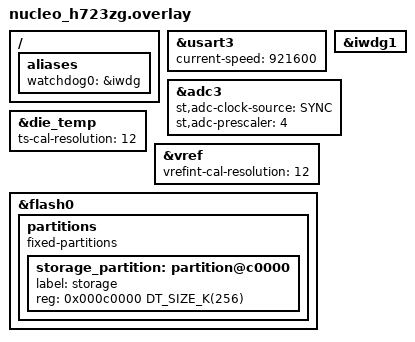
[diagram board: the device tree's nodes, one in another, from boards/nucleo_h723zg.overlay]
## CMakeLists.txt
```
cmake_minimum_required(VERSION 3.20.0)
find_package(Zephyr REQUIRED HINTS $ENV{ZEPHYR_BASE})
project(motor)

target_sources(app PRIVATE src/main.c src/control.c src/tune.c src/health.c src/settings.c)
```

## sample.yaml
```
sample:
  name: Motor controller node
common:
  platform_allow:
    - nucleo_h723zg
    - nucleo_h753zi
  integration_platforms:
    - nucleo_h753zi
tests:
  zelos.nodes.motor: {}
```

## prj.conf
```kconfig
# A motor controller whose debug interface is its serial console: Zephyr's log
# and its shell share the board's console UART.
CONFIG_LOG=y
CONFIG_SHELL=y

# Deferred logging, so the control loop copies a message into a buffer and
# never waits on the UART. 16 KiB holds about a second of output at full rate.
CONFIG_LOG_MODE_DEFERRED=y
CONFIG_LOG_BUFFER_SIZE=16384
# Flush every message, so command replies never land among stale lines.
CONFIG_LOG_PROCESS_TRIGGER_THRESHOLD=1
# printk goes through the log too, unprefixed: the Teleplot points.
CONFIG_LOG_PRINTK=y

# The control law runs in single-precision float on the Cortex-M7's FPU, and
# the log prints floats.
CONFIG_FPU=y
CONFIG_CBPRINTF_FP_SUPPORT=y

# LEDs, the user button, and the die temperature and VREF sensors.
CONFIG_GPIO=y
CONFIG_SENSOR=y
CONFIG_ADC=y

# CPU load, from the scheduler's own cycle accounting.
CONFIG_THREAD_RUNTIME_STATS=y
CONFIG_SCHED_THREAD_USAGE_ALL=y

# Why the board last reset: power-on, pin, software, watchdog or a crash.
CONFIG_HWINFO=y

# The hardware watchdog: a stalled control loop resets the board.
CONFIG_WATCHDOG=y

# Tuning saved to flash, so it survives a reset. ZMS, not NVS: NVS addresses
# at most 64 KiB sectors, and the STM32H7 erases 128 KiB at a time.
CONFIG_FLASH=y
CONFIG_FLASH_MAP=y
CONFIG_ZMS=y
CONFIG_SETTINGS=y
CONFIG_SETTINGS_ZMS=y

# A crash prints its dump, records where it happened, and the board restarts,
# as a field unit would; main.c's fatal error handler does the restart.
CONFIG_REBOOT=y
CONFIG_THREAD_NAME=y

# The control loop, the health thread and the shell all use the FPU.
CONFIG_FPU_SHARING=y

CONFIG_MAIN_STACK_SIZE=4096
CONFIG_SHELL_STACK_SIZE=4096
```

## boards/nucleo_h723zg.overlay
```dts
/*
 * NUCLEO-H723ZG: the board the serial-board bench runs on. The board file
 * enables none of these, so the node does.
 */

/ {
	aliases {
		watchdog0 = &iwdg;
	};
};

/* The console at 921600 baud: the ST-LINK-V3's virtual COM port carries it. */
&usart3 {
	current-speed = <921600>;
};

&iwdg1 {
	status = "okay";
};

/* The die temperature and VREFINT sensors read internal channels of ADC3. */
&adc3 {
	st,adc-clock-source = "SYNC";
	st,adc-prescaler = <4>;
	status = "okay";
};

/*
 * The H72x keeps its factory calibration of these channels at ADC3's 12-bit
 * resolution; the H7 family file says 16, which reads VDDA 16 times too low.
 */
&die_temp {
	ts-cal-resolution = <12>;
	status = "okay";
};

&vref {
	vrefint-cal-resolution = <12>;
	status = "okay";
};

/* The last two 128 KiB sectors hold the saved tuning. */
&flash0 {
	partitions {
		compatible = "fixed-partitions";
		#address-cells = <1>;
		#size-cells = <1>;

		storage_partition: partition@c0000 {
			label = "storage";
			reg = <0x000c0000 DT_SIZE_K(256)>;
		};
	};
};
```

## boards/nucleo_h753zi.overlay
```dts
/* NUCLEO-H753ZI, the board CI builds every node for: the same console speed and sensors. */

&usart3 {
	current-speed = <921600>;
};

&vref {
	status = "okay";
};
```

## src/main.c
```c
/*
 * Motor controller.
 *
 * A brushed DC motor speed controller whose debug interface is its serial
 * console, the way most boards on a bench are brought up. The log and the
 * shell share the console UART:
 *
 *   motor target <rpm>    the speed target, -6000 to 6000
 *   motor load <Nm>       an external load torque, 0 to 0.15
 *   motor stop | status
 *   pid show | save | defaults
 *   pid kp|ki|kd <value>  tune the speed loop live
 *   fault crash | hang | dump
 *
 * At boot it logs its version, why the board reset, and, if the last run
 * crashed, where. A crash record lives in RAM that survives the reset.
 */

#include <stdlib.h>
#include <string.h>

#include <zephyr/drivers/hwinfo.h>
#include <zephyr/fatal.h>
#include <zephyr/kernel.h>
#include <zephyr/linker/section_tags.h>
#include <zephyr/logging/log.h>
#include <zephyr/logging/log_ctrl.h>
#include <zephyr/shell/shell.h>
#include <zephyr/sys/reboot.h>

#include "motor.h"

LOG_MODULE_REGISTER(app, LOG_LEVEL_INF);

#define CRASH_MAGIC 0xC0FFEE42u

/* Not cleared at boot: written by the fatal error handler, read after the reset. */
static __noinit struct {
	uint32_t magic;
	uint32_t reason;
	uint32_t pc;
	char thread[16];
} crash;

void k_sys_fatal_error_handler(unsigned int reason, const struct arch_esf *esf)
{
	const char *name = k_thread_name_get(k_current_get());

	crash.magic = CRASH_MAGIC;
	crash.reason = reason;
	crash.pc = esf != NULL ? esf->basic.pc : 0;
	strncpy(crash.thread, name != NULL ? name : "?", sizeof(crash.thread) - 1);
	crash.thread[sizeof(crash.thread) - 1] = '\0';

	LOG_ERR("rebooting after fatal error %u", reason);
	LOG_PANIC();
	sys_reboot(SYS_REBOOT_COLD);
	CODE_UNREACHABLE;
}

static const char *reset_cause(uint32_t cause)
{
	/* The most telling cause first: a watchdog reset also sets the pin flag. */
	if (cause & RESET_WATCHDOG) {
		return "watchdog";
	}
	if (cause & RESET_SOFTWARE) {
		return "software";
	}
	if (cause & RESET_BROWNOUT) {
		return "brownout";
	}
	if (cause & RESET_POR) {
		return "power-on";
	}
	if (cause & RESET_PIN) {
		return "reset-pin";
	}
	return "unknown";
}

static void report_boot(void)
{
	uint32_t cause = 0;

	hwinfo_get_reset_cause(&cause);
	hwinfo_clear_reset_cause();

	LOG_INF("motor-ctl v%s board=%s reset=%s", FW_VERSION, CONFIG_BOARD, reset_cause(cause));

	if (crash.magic == CRASH_MAGIC) {
		LOG_ERR("previous run crashed reason=%u pc=0x%08x thread=%s", crash.reason,
			crash.pc, crash.thread);
	} else if (cause & RESET_WATCHDOG) {
		LOG_ERR("previous run stopped feeding the watchdog");
	}
	crash.magic = 0;
}

/* "1500", "-2.5" and "0.05" are numbers; "", "12x" and "1e999" are not. */
static int parse(const struct shell *sh, const char *s, float lo, float hi, float *out)
{
	char *end;
	const float v = strtof(s, &end);

	if (end == s || *end != '\0' || v < lo || v > hi) {
		shell_error(sh, "expected a number from %g to %g", (double)lo, (double)hi);
		return -EINVAL;
	}
	*out = v;
	return 0;
}

static int cmd_target(const struct shell *sh, size_t argc, char **argv)
{
	float rpm;

	if (parse(sh, argv[1], -6000.0f, 6000.0f, &rpm) != 0) {
		return -EINVAL;
	}
	control_set_target(rpm);
	shell_print(sh, "target %.0f rpm", (double)rpm);
	return 0;
}

static int cmd_load(const struct shell *sh, size_t argc, char **argv)
{
	float nm;

	if (parse(sh, argv[1], 0.0f, 0.15f, &nm) != 0) {
		return -EINVAL;
	}
	control_set_load(nm);
	shell_print(sh, "load %.3f Nm", (double)nm);
	return 0;
}

static int cmd_stop(const struct shell *sh, size_t argc, char **argv)
{
	control_set_target(0.0f);
	shell_print(sh, "target 0 rpm");
	return 0;
}

static int cmd_status(const struct shell *sh, size_t argc, char **argv)
{
	const struct pid_gains g = control_gains();

	shell_print(sh, "target   %.0f rpm", (double)control_target());
	shell_print(sh, "load     %.3f Nm", (double)control_load());
	shell_print(sh, "limiting %s", control_limiting() ? "yes" : "no");
	shell_print(sh, "winding  %.1f C", (double)control_winding_c());
	shell_print(sh, "gains    kp=%.4f ki=%.3f kd=%.4f", (double)g.kp, (double)g.ki,
		    (double)g.kd);
	return 0;
}

static int cmd_pid_show(const struct shell *sh, size_t argc, char **argv)
{
	const struct pid_gains g = control_gains();

	shell_print(sh, "kp %.4f A/rpm", (double)g.kp);
	shell_print(sh, "ki %.3f A/(rpm s)", (double)g.ki);
	shell_print(sh, "kd %.4f A s/rpm", (double)g.kd);
	return 0;
}

static int cmd_pid_gain(const struct shell *sh, size_t argc, char **argv)
{
	struct pid_gains g = control_gains();
	float *field = strcmp(argv[0], "kp") == 0   ? &g.kp
		       : strcmp(argv[0], "ki") == 0 ? &g.ki
						    : &g.kd;
	float v;

	if (parse(sh, argv[1], 0.0f, 10.0f, &v) != 0) {
		return -EINVAL;
	}
	*field = v;
	control_set_gains(g);
	tuning_report("gains changed");
	shell_print(sh, "%s %g", argv[0], (double)v);
	return 0;
}

static int cmd_pid_save(const struct shell *sh, size_t argc, char **argv)
{
	return tuning_save();
}

static int cmd_pid_defaults(const struct shell *sh, size_t argc, char **argv)
{
	control_set_gains(PID_DEFAULTS);
	tuning_report("gains reset to defaults");
	return 0;
}

static int cmd_fault_crash(const struct shell *sh, size_t argc, char **argv)
{
	LOG_WRN("executing an undefined instruction on purpose");
	k_msleep(20);
	/* A real CPU exception, the kind a corrupted function pointer causes. */
	__asm__ volatile("udf #0");
	return 0;
}

static int cmd_fault_hang(const struct shell *sh, size_t argc, char **argv)
{
	LOG_WRN("stalling the control loop on purpose; the watchdog resets the board in 100 ms");
	k_msleep(20);
	control_stall();
	return 0;
}

static int cmd_fault_dump(const struct shell *sh, size_t argc, char **argv)
{
	const struct pid_gains g = control_gains();

	LOG_HEXDUMP_INF(&g, sizeof(g), "pid gains as stored in flash");
	return 0;
}

SHELL_STATIC_SUBCMD_SET_CREATE(motor_cmds,
	SHELL_CMD_ARG(target, NULL, "<rpm>  Speed target, -6000 to 6000", cmd_target, 2, 0),
	SHELL_CMD_ARG(load, NULL, "<Nm>  Load torque, 0 to 0.15", cmd_load, 2, 0),
	SHELL_CMD_ARG(stop, NULL, "Target 0 rpm", cmd_stop, 1, 0),
	SHELL_CMD_ARG(status, NULL, "Show the controller's state", cmd_status, 1, 0),
	SHELL_SUBCMD_SET_END);
SHELL_CMD_REGISTER(motor, &motor_cmds, "Motor speed control", NULL);

SHELL_STATIC_SUBCMD_SET_CREATE(pid_cmds,
	SHELL_CMD_ARG(show, NULL, "Show the speed loop's gains", cmd_pid_show, 1, 0),
	SHELL_CMD_ARG(kp, NULL, "<value>  Proportional gain, A/rpm", cmd_pid_gain, 2, 0),
	SHELL_CMD_ARG(ki, NULL, "<value>  Integral gain, A/(rpm s)", cmd_pid_gain, 2, 0),
	SHELL_CMD_ARG(kd, NULL, "<value>  Derivative gain, A s/rpm", cmd_pid_gain, 2, 0),
	SHELL_CMD_ARG(save, NULL, "Save the gains to flash", cmd_pid_save, 1, 0),
	SHELL_CMD_ARG(defaults, NULL, "Restore the shipped gains", cmd_pid_defaults, 1, 0),
	SHELL_SUBCMD_SET_END);
SHELL_CMD_REGISTER(pid, &pid_cmds, "Speed loop tuning", NULL);

SHELL_STATIC_SUBCMD_SET_CREATE(fault_cmds,
	SHELL_CMD_ARG(crash, NULL, "Execute an undefined instruction", cmd_fault_crash, 1, 0),
	SHELL_CMD_ARG(hang, NULL, "Stall the control loop until the watchdog fires",
		      cmd_fault_hang, 1, 0),
	SHELL_CMD_ARG(dump, NULL, "Hex-dump the stored gains", cmd_fault_dump, 1, 0),
	SHELL_SUBCMD_SET_END);
SHELL_CMD_REGISTER(fault, &fault_cmds, "Inject faults", NULL);

int main(void)
{
	report_boot();
	tuning_load();
	return 0;
}
```

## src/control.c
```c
/*
 * The speed loop: a PI controller (with an optional D term) at 1 kHz, giving a
 * current reference to an inner current loop, limited to I_LIMIT_A.
 *
 * The motor is a model on the chip: a brushed DC motor on a 24 V bus, its
 * winding inductance, back-EMF, rotor inertia, friction and an external load
 * torque, integrated in ten 100 us sub-steps per control period. The winding
 * heats with I^2R and cools to the die temperature the health thread measures.
 *
 * Logged at 100 Hz from module motor, with the speed error as a Teleplot point.
 * After every change of target, module tune logs the step's rise time,
 * overshoot and settling time, measured on the chip.
 */

#include <math.h>

#include <zephyr/drivers/watchdog.h>
#include <zephyr/kernel.h>
#include <zephyr/logging/log.h>
#include <zephyr/spinlock.h>
#include <zephyr/sys/atomic.h>
#include <zephyr/sys/printk.h>

#include "motor.h"

LOG_MODULE_REGISTER(motor, LOG_LEVEL_INF);

#define PERIOD_US 1000
#define SUBSTEPS 10
#define DT (PERIOD_US * 1e-6f)
#define SUB_DT (DT / SUBSTEPS)
#define TELEMETRY_EVERY 10 /* periods: 100 Hz */

/* The motor: Maxon-class 24 V brushed DC. */
#define R_OHM 0.6f
#define L_H 1.0e-3f
#define K_NM_PER_A 0.035f /* torque constant = back-EMF constant */
#define J_KGM2 4.0e-5f
#define B_NMS 2.0e-6f
#define VBUS 24.0f
#define CURRENT_LOOP_GAIN 40.0f /* V per A of current error */
#define RPM_PER_RAD_S (60.0f / (2.0f * 3.14159265f))

#define I_LIMIT_A 5.0f
#define I_DERATED_A 2.5f
#define WINDING_HOT_C 80.0f
#define WINDING_TRIP_C 100.0f
#define R_TH_K_PER_W 4.0f
#define C_TH_J_PER_K 20.0f

static struct k_spinlock lock;
static struct pid_gains gains = PID_DEFAULTS;
static float target_rpm;
static float load_nm;
static float ambient_c = 25.0f;

/* Read by the health thread. */
static atomic_t limiting;
static atomic_t loop_max_us;
static atomic_t stall;
static float winding_c = 25.0f;

static const struct device *const wdt = DEVICE_DT_GET(DT_ALIAS(watchdog0));
static int wdt_channel = -1;

void control_set_target(float rpm)
{
	k_spinlock_key_t key = k_spin_lock(&lock);

	tune_begin(target_rpm, rpm, k_uptime_get());
	target_rpm = rpm;
	k_spin_unlock(&lock, key);
}

float control_target(void)
{
	return target_rpm;
}

void control_set_load(float nm)
{
	load_nm = nm;
}

float control_load(void)
{
	return load_nm;
}

struct pid_gains control_gains(void)
{
	k_spinlock_key_t key = k_spin_lock(&lock);
	struct pid_gains g = gains;

	k_spin_unlock(&lock, key);
	return g;
}

void control_set_gains(struct pid_gains g)
{
	k_spinlock_key_t key = k_spin_lock(&lock);

	gains = g;
	k_spin_unlock(&lock, key);
}

bool control_limiting(void)
{
	return atomic_get(&limiting) != 0;
}

float control_winding_c(void)
{
	return winding_c;
}

uint32_t control_take_loop_max_us(void)
{
	return (uint32_t)atomic_set(&loop_max_us, 0);
}

void control_set_ambient(float celsius)
{
	ambient_c = celsius;
}

void control_stall(void)
{
	atomic_set(&stall, 1);
}

static void watchdog_start(void)
{
	const struct wdt_timeout_cfg cfg = {
		.window.min = 0,
		.window.max = 100, /* ms: a hundred missed control periods */
		.callback = NULL,
		.flags = WDT_FLAG_RESET_SOC,
	};

	if (!device_is_ready(wdt)) {
		LOG_ERR("watchdog not ready");
		return;
	}
	wdt_channel = wdt_install_timeout(wdt, &cfg);
	if (wdt_channel < 0 || wdt_setup(wdt, WDT_OPT_PAUSE_HALTED_BY_DBG) < 0) {
		LOG_ERR("watchdog setup failed: %d", wdt_channel);
		wdt_channel = -1;
		return;
	}
	LOG_INF("watchdog armed, 100 ms timeout");
}

static void control_thread(void *a, void *b, void *c)
{
	float w = 0.0f;     /* rotor speed, rad/s */
	float i = 0.0f;     /* winding current, A */
	float integ = 0.0f; /* integral term, A */
	float prev_err = 0.0f;
	bool hot = false;
	bool tripped = false;
	uint32_t saturated_ms = 0;
	uint32_t free_ms = 0;
	bool limit_reported = false;
	uint64_t next = k_uptime_ticks();

	watchdog_start();

	for (uint32_t n = 0;; n++) {
		const uint32_t t0 = k_cycle_get_32();

		if (atomic_get(&stall)) {
			/* What a deadlocked driver looks like: the loop stops feeding the watchdog. */
			for (;;) {
				k_busy_wait(1000);
			}
		}

		k_spinlock_key_t key = k_spin_lock(&lock);
		const struct pid_gains g = gains;
		const float target = target_rpm;
		k_spin_unlock(&lock, key);

		const float rpm = w * RPM_PER_RAD_S;
		const float err = target - rpm;
		const float deriv = (err - prev_err) / DT;
		const float limit = tripped ? I_DERATED_A : I_LIMIT_A;

		prev_err = err;

		const float iref_free = g.kp * err + integ + g.kd * deriv;
		const float iref = CLAMP(iref_free, -limit, limit);
		const bool saturated = iref != iref_free;

		/* Anti-windup: hold the integrator while the output is limited. */
		if (!saturated) {
			integ += g.ki * err * DT;
		}

		for (int s = 0; s < SUBSTEPS; s++) {
			const float v = CLAMP(R_OHM * iref + K_NM_PER_A * w +
						      CURRENT_LOOP_GAIN * (iref - i),
					      -VBUS, VBUS);

			i += (v - R_OHM * i - K_NM_PER_A * w) / L_H * SUB_DT;
			w += (K_NM_PER_A * i - B_NMS * w - load_nm) / J_KGM2 * SUB_DT;
		}

		/* The winding heats with I^2R and cools to the board's own temperature. */
		winding_c += (i * i * R_OHM - (winding_c - ambient_c) / R_TH_K_PER_W) /
			     C_TH_J_PER_K * DT;

		const int64_t now = k_uptime_get();
		const float duty = 100.0f * (R_OHM * i + K_NM_PER_A * w) / VBUS;

		tune_sample(w * RPM_PER_RAD_S, now);

		if (saturated) {
			saturated_ms++;
			free_ms = 0;
		} else {
			free_ms++;
			saturated_ms = 0;
		}
		if (saturated_ms == 50 && !limit_reported) {
			LOG_WRN("current limit demand=%.2fA limit=%.1fA", (double)iref_free,
				(double)limit);
			limit_reported = true;
		}
		if (free_ms == 100) {
			limit_reported = false;
		}
		atomic_set(&limiting, saturated_ms >= 50);

		if (!hot && winding_c > WINDING_HOT_C) {
			LOG_WRN("winding hot winding=%.1fC", (double)winding_c);
			hot = true;
		} else if (hot && winding_c < WINDING_HOT_C - 5.0f) {
			hot = false;
		}
		if (!tripped && winding_c > WINDING_TRIP_C) {
			LOG_ERR("winding over temperature, derating winding=%.1fC limit=%.1fA",
				(double)winding_c, (double)I_DERATED_A);
			tripped = true;
		} else if (tripped && winding_c < WINDING_TRIP_C - 10.0f) {
			LOG_INF("winding cooled, full current winding=%.1fC limit=%.1fA",
				(double)winding_c, (double)I_LIMIT_A);
			tripped = false;
		}

		if (n % TELEMETRY_EVERY == 0) {
			LOG_INF("speed=%.0frpm target=%.0frpm current=%.2fA duty=%.1f%% winding=%.1fC",
				(double)(w * RPM_PER_RAD_S), (double)target, (double)i,
				(double)duty, (double)winding_c);
			printk(">error:%.1f\xc2\xa7rpm\n", (double)err);
		}

		if (wdt_channel >= 0) {
			wdt_feed(wdt, wdt_channel);
		}

		const uint32_t used_us = k_cyc_to_us_ceil32(k_cycle_get_32() - t0);

		/*
		 * Not one atomic step: the health thread may zero the maximum between
		 * the read and the write. It reads once a second, so at worst one
		 * period's time lands in the next report.
		 */
		if ((atomic_val_t)used_us > atomic_get(&loop_max_us)) {
			atomic_set(&loop_max_us, used_us);
		}
		if (used_us > PERIOD_US / 2) {
			LOG_WRN("control loop overrun used=%uus budget=%uus", used_us, PERIOD_US / 2);
		}

		next += k_us_to_ticks_ceil64(PERIOD_US);
		k_sleep(K_TIMEOUT_ABS_TICKS(next));
	}
}

K_THREAD_DEFINE(control_tid, 2048, control_thread, NULL, NULL, NULL, 2, K_FP_REGS, 1000);
```

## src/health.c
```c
/*
 * The chip's own state, once a second from module sys: CPU load from the
 * scheduler's cycle accounting, the control loop's worst execution time, and
 * the die temperature and VDDA from the on-chip sensors. The die temperature
 * is the motor model's ambient.
 *
 * LEDs: green blinks while the firmware runs, yellow lights while the current
 * limit holds, red while the winding is hot. The user button steps the target
 * through 0, 1500 and 3000 rpm.
 */

#include <zephyr/drivers/gpio.h>
#include <zephyr/drivers/sensor.h>
#include <zephyr/kernel.h>
#include <zephyr/logging/log.h>

#include "motor.h"

LOG_MODULE_REGISTER(sys, LOG_LEVEL_INF);

#define TICK_MS 100
#define REPORT_EVERY (MSEC_PER_SEC / TICK_MS)

static const struct gpio_dt_spec green = GPIO_DT_SPEC_GET(DT_ALIAS(led0), gpios);
static const struct gpio_dt_spec yellow = GPIO_DT_SPEC_GET(DT_ALIAS(led1), gpios);
/* The NUCLEO-H753ZI has its red LED only as a PWM LED, so it may be absent. */
static const struct gpio_dt_spec red = GPIO_DT_SPEC_GET_OR(DT_ALIAS(led2), gpios, {0});
static const struct gpio_dt_spec button = GPIO_DT_SPEC_GET(DT_ALIAS(sw0), gpios);

static const struct device *const die = DEVICE_DT_GET(DT_NODELABEL(die_temp));
static const struct device *const vref = DEVICE_DT_GET(DT_NODELABEL(vref));

static const float button_targets[] = {1500.0f, 3000.0f, 0.0f};
static struct gpio_callback button_cb;
static struct k_work button_work;
static uint32_t presses;

static void button_pressed(struct k_work *work)
{
	const float target = button_targets[presses % ARRAY_SIZE(button_targets)];

	presses++;
	LOG_INF("button press=%u target=%.0frpm", presses, (double)target);
	control_set_target(target);
}

/* No debounce in software: the NUCLEO's user button has an RC filter on the board. */
static void button_isr(const struct device *dev, struct gpio_callback *cb, uint32_t pins)
{
	k_work_submit(&button_work);
}

static int read_sensor(const struct device *dev, enum sensor_channel chan, float *out)
{
	struct sensor_value v;

	if (!device_is_ready(dev) || sensor_sample_fetch(dev) != 0 ||
	    sensor_channel_get(dev, chan, &v) != 0) {
		return -EIO;
	}
	*out = (float)sensor_value_to_double(&v);
	return 0;
}

static void io_init(void)
{
	gpio_pin_configure_dt(&green, GPIO_OUTPUT_INACTIVE);
	gpio_pin_configure_dt(&yellow, GPIO_OUTPUT_INACTIVE);
	if (red.port != NULL) {
		gpio_pin_configure_dt(&red, GPIO_OUTPUT_INACTIVE);
	}

	k_work_init(&button_work, button_pressed);
	gpio_pin_configure_dt(&button, GPIO_INPUT);
	gpio_pin_interrupt_configure_dt(&button, GPIO_INT_EDGE_TO_ACTIVE);
	gpio_init_callback(&button_cb, button_isr, BIT(button.pin));
	gpio_add_callback(button.port, &button_cb);
}

static void health_thread(void *a, void *b, void *c)
{
	k_thread_runtime_stats_t prev, now;
	bool sensors_warned = false;

	io_init();
	k_thread_runtime_stats_all_get(&prev);

	for (uint32_t n = 1;; n++) {
		k_msleep(TICK_MS);

		gpio_pin_set_dt(&green, (n / 5) % 2);
		gpio_pin_set_dt(&yellow, control_limiting());
		if (red.port != NULL) {
			gpio_pin_set_dt(&red, control_winding_c() > 80.0f);
		}

		if (n % REPORT_EVERY != 0) {
			continue;
		}

		k_thread_runtime_stats_all_get(&now);
		const uint64_t total = now.execution_cycles - prev.execution_cycles;
		const uint64_t idle = now.idle_cycles - prev.idle_cycles;
		const float cpu = total ? 100.0f * (float)(total - idle) / (float)total : 0.0f;

		prev = now;

		float die_c, vdda;

		if (read_sensor(die, SENSOR_CHAN_DIE_TEMP, &die_c) != 0 ||
		    read_sensor(vref, SENSOR_CHAN_VOLTAGE, &vdda) != 0) {
			if (!sensors_warned) {
				LOG_WRN("on-chip sensors unavailable");
				sensors_warned = true;
			}
			LOG_INF("cpu=%.1f%% loop_max=%uus uptime=%llds", (double)cpu,
				control_take_loop_max_us(), k_uptime_get() / MSEC_PER_SEC);
			continue;
		}
		control_set_ambient(die_c);
		LOG_INF("cpu=%.1f%% loop_max=%uus die=%.1fC vdda=%.3fV uptime=%llds", (double)cpu,
			control_take_loop_max_us(), (double)die_c, (double)vdda,
			k_uptime_get() / MSEC_PER_SEC);
	}
}

K_THREAD_DEFINE(health_tid, 2048, health_thread, NULL, NULL, NULL, 5, K_FP_REGS, 500);
```

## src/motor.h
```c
/*
 * A brushed DC motor speed controller. The motor itself is simulated on the
 * chip, since none is wired to the board; everything around it is what a real
 * controller does: a 1 kHz control loop with a measured period, a current
 * limit, thermal derating, a watchdog, tuning saved to flash, and crash
 * forensics that survive a reset.
 */

#ifndef MOTOR_H_
#define MOTOR_H_

#include <stdbool.h>
#include <stdint.h>

#define FW_VERSION "1.4.2"

struct pid_gains {
	float kp; /* A per rpm of speed error */
	float ki; /* A per rpm-second */
	float kd; /* A per rpm-per-second */
};

/* As a fresh unit ships: stable, but it rings. */
#define PID_DEFAULTS ((struct pid_gains){.kp = 0.002f, .ki = 0.1f, .kd = 0.0f})

/* control.c: the 1 kHz loop and the simulated motor. */
void control_set_target(float rpm);
float control_target(void);
void control_set_load(float nm);
float control_load(void);
struct pid_gains control_gains(void);
void control_set_gains(struct pid_gains gains);
bool control_limiting(void);
float control_winding_c(void);
uint32_t control_take_loop_max_us(void);
void control_set_ambient(float celsius);
void control_stall(void);

/* tune.c: step-response metrics, measured on the chip. */
void tune_begin(float from_rpm, float to_rpm, int64_t now_ms);
void tune_sample(float rpm, int64_t now_ms);

/* settings.c: the tuning in flash. */
int tuning_load(void);
int tuning_save(void);
void tuning_report(const char *what);

#endif /* MOTOR_H_ */
```

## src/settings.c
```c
/*
 * The tuning in flash, through Zephyr's settings subsystem on NVS: tune live
 * from the shell, `pid save`, and the next boot starts from those gains.
 */

#include <zephyr/kernel.h>
#include <zephyr/logging/log.h>
#include <zephyr/settings/settings.h>

#include "motor.h"

LOG_MODULE_REGISTER(config, LOG_LEVEL_INF);

static bool loaded;

static int pid_set(const char *name, size_t len, settings_read_cb read_cb, void *cb_arg)
{
	struct pid_gains g;

	if (!settings_name_steq(name, "gains", NULL)) {
		return -ENOENT;
	}
	if (len != sizeof(g) || read_cb(cb_arg, &g, sizeof(g)) != sizeof(g)) {
		LOG_WRN("saved tuning has the wrong size, using defaults");
		return -EINVAL;
	}
	control_set_gains(g);
	loaded = true;
	return 0;
}

SETTINGS_STATIC_HANDLER_DEFINE(pid, "pid", NULL, pid_set, NULL, NULL);

int tuning_load(void)
{
	int err = settings_subsys_init();

	if (err == 0) {
		err = settings_load();
	}
	if (err != 0) {
		LOG_ERR("settings unavailable, using defaults: %d", err);
	}

	const struct pid_gains g = control_gains();

	LOG_INF("%s kp=%.4f ki=%.3f kd=%.4f", loaded ? "tuning loaded from flash" : "no saved tuning, defaults",
		(double)g.kp, (double)g.ki, (double)g.kd);
	return err;
}

/* Every change of the gains from module config, so they are one set of signals. */
void tuning_report(const char *what)
{
	const struct pid_gains g = control_gains();

	LOG_INF("%s kp=%.4f ki=%.3f kd=%.4f", what, (double)g.kp, (double)g.ki, (double)g.kd);
}

int tuning_save(void)
{
	const struct pid_gains g = control_gains();
	const int err = settings_save_one("pid/gains", &g, sizeof(g));

	if (err != 0) {
		LOG_ERR("saving tuning failed: %d", err);
		return err;
	}
	LOG_INF("tuning saved to flash kp=%.4f ki=%.3f kd=%.4f", (double)g.kp, (double)g.ki,
		(double)g.kd);
	return 0;
}
```

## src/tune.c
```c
/*
 * Step-response metrics: after every change of target, the rise time (to 90 %
 * of the step), the overshoot (past the target, as a share of the step) and
 * the settling time (until the speed stays within 2 % of the step for 200 ms),
 * measured from the control loop's own samples and logged from module tune.
 */

#include <math.h>

#include <zephyr/kernel.h>
#include <zephyr/logging/log.h>
#include <zephyr/spinlock.h>

#include "motor.h"

LOG_MODULE_REGISTER(tune, LOG_LEVEL_INF);

#define SETTLE_BAND 0.02f
#define SETTLE_HOLD_MS 200
#define TIMEOUT_MS 3000

static struct k_spinlock lock;

static struct {
	bool active;
	float from;
	float to;
	int64_t start_ms;
	float peak_excess;   /* furthest past the target, in rpm */
	int64_t rise_ms;     /* when the speed first reached 90 % of the step, or -1 */
	int64_t last_out_ms; /* the last sample outside the band */
} step;

void tune_begin(float from_rpm, float to_rpm, int64_t now_ms)
{
	k_spinlock_key_t key = k_spin_lock(&lock);

	step.active = to_rpm != from_rpm;
	step.from = from_rpm;
	step.to = to_rpm;
	step.start_ms = now_ms;
	step.peak_excess = 0.0f;
	step.rise_ms = -1;
	step.last_out_ms = now_ms;
	k_spin_unlock(&lock, key);
}

void tune_sample(float rpm, int64_t now_ms)
{
	k_spinlock_key_t key = k_spin_lock(&lock);

	if (!step.active) {
		k_spin_unlock(&lock, key);
		return;
	}

	const float size = step.to - step.from;
	/* Signed, so a step down counts its undershoot as overshoot. */
	const float progress = (rpm - step.from) / size;
	const float excess = (rpm - step.to) * (size > 0.0f ? 1.0f : -1.0f);

	if (step.rise_ms < 0 && progress >= 0.9f) {
		step.rise_ms = now_ms - step.start_ms;
	}
	step.peak_excess = MAX(step.peak_excess, excess);
	if (fabsf(rpm - step.to) > SETTLE_BAND * fabsf(size)) {
		step.last_out_ms = now_ms;
	}

	const bool settled = now_ms - step.last_out_ms >= SETTLE_HOLD_MS;
	const bool timed_out = now_ms - step.start_ms >= TIMEOUT_MS;

	if (!settled && !timed_out) {
		k_spin_unlock(&lock, key);
		return;
	}

	/* Copied out, so nothing logs under the lock. */
	const float from = step.from;
	const float to = step.to;
	const float overshoot = 100.0f * step.peak_excess / fabsf(size);
	const int64_t rise = step.rise_ms;
	const int64_t settle = step.last_out_ms - step.start_ms;

	step.active = false;
	k_spin_unlock(&lock, key);

	if (!settled) {
		LOG_WRN("step from=%.0frpm to=%.0frpm did not settle within %dms", (double)from,
			(double)to, TIMEOUT_MS);
		return;
	}
	LOG_INF("step from=%.0frpm to=%.0frpm rise=%lldms overshoot=%.1f%% settle=%lldms",
		(double)from, (double)to, rise, (double)overshoot, settle);
}
```
